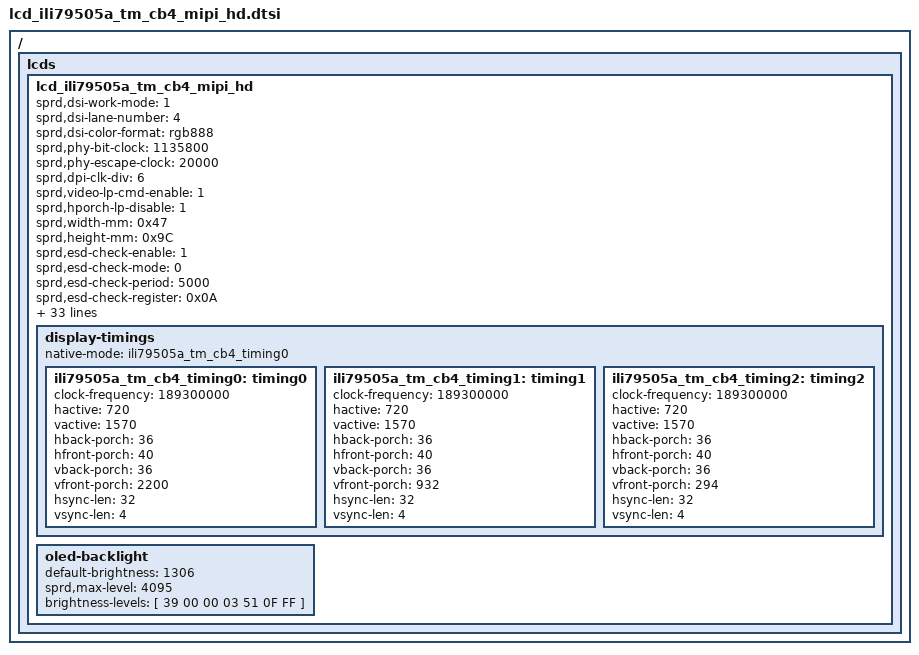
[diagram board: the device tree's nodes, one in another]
/*
 * R61350 Truly LCD config dtsi file for spreadtrum
 *
 * Copyright (C) 2018, Spreadtrum Communications Inc.
 *
 * SPDX-License-Identifier: (GPL-2.0+ OR MIT)
 */

/ {
    fragment {
        target-path = "/";
        __overlay__ {
            lcds {
                lcd_ili79505a_tm_cb4_mipi_hd: lcd_ili79505a_tm_cb4_mipi_hd {

                sprd,dsi-work-mode = <1>; /* video burst mode*/
                sprd,dsi-lane-number = <4>;
                sprd,dsi-color-format = "rgb888";

                sprd,phy-bit-clock = <1135800>; /* kbps */
                sprd,phy-escape-clock = <20000>;/* kHz */
                sprd,dpi-clk-div = <6>;
                sprd,video-lp-cmd-enable = <1>;
                sprd,hporch-lp-disable = <1>;

                sprd,width-mm = <0x47>;
                sprd,height-mm = <0x9C>;
                sprd,esd-check-enable = <1>;
                sprd,esd-check-mode = <0>;
                sprd,esd-check-period = <5000>;
                sprd,esd-check-register = <0x0A>;
                sprd,esd-check-value = <0x9C>;
                sprd,vrr-enabled;
                sprd,vrr-max-layers = <2>;

                sprd,low-brightness = <1>;

                sprd,power-i2c-bus = <4>;
                sprd,power-i2c-addr = <0x3e>;
                sprd,power-i2c-reg = [00 01 03];
                sprd,power-i2c-val = [14 14 33];

                sprd,reset-on-sequence = <1 5>, <0 5>, <1 5>;
                sprd,reset-off-sequence = <1 5>;

                sprd,tp-resume-by-ddic = <1>;
                sprd,tp-aod-support = <1>;

                sprd,mipi-lastframe-delay = <5>; //ms
                sprd,mipi-lastframe-delay-switch = <1>; //1 on; 0 off

                /*
                 * Use 4 bits number for descripting video lp mode, and it can be combined used.
                 * BIT(0): allow vactive enter lp;
                 * BIT(1): allow vfp enter lp;
                 * BIT(2): allow vbp enter lp;
                 * BIT(3): allow vsa enter lp;
                 * For example:
                 * If we need vfp & vbp enter lp, we can calculate this value as a result of BIT(1) | BIT(2)
                 * And we get the result of 3 and set this value to lcd dt property sprd,video-lp-en-mode.
                 * If we need all stage can enter lp, we can calculate this value as a result of BIT(0) | BIT(1) | BIT(2) | BIT(3).
                 * And we get the result of 15 and set this value to lcd dt property sprd,video-lp-en-mode.
                 */
                /*sprd,video-lp-en-mode = <2>;*/
                sprd,use-dcs-write;
                sprd,initial-command = [
                39 00 00 04 FF 5A A5 06
                23 00 00 02 07 A4
                39 00 00 04 FF 5A A5 03
                23 00 00 02 83 20
                23 00 00 02 84 01
                39 00 00 04 FF 5A A5 00
                23 00 00 02 53 2C
                23 00 00 03 51 0f ff
                23 00 00 03 68 04 00
                23 00 00 02 35 00
                23 3d 00 02 11 00
                23 60 00 02 29 00
                ];

                sprd,sleep-in-command = [
                05 32 00 01 28
                05 78 00 01 10
                ];

                sprd,sleep-in-command-gesture-off = [
                05 32 00 01 28
                05 78 00 01 10
                ];

                sprd,sleep-out-command = [
                05 80 00 01 11
                05 14 00 01 29
                ];

                sprd,doze-in-command = [
                23 00 00 02 53 24
                ];

                sprd,doze-out-command = [
                23 00 00 02 53 2C
                ];

                sprd,cabc-off-command = [
                39 00 00 04 FF 5A A5 00
                23 00 00 02 55 01
                ];
                sprd,cabc-ui-command = [
                39 00 00 04 FF 5A A5 00
                23 00 00 02 55 01
                ];
                sprd,cabc-still-command = [
                39 00 00 04 FF 5A A5 00
                23 00 00 02 55 02
                ];
                sprd,cabc-moving-command = [
                39 00 00 04 FF 5A A5 00
                23 00 00 02 55 03
                ];

                display-timings {
                    native-mode = <&ili79505a_tm_cb4_timing0>;

                    ili79505a_tm_cb4_timing0: timing0 {
                            clock-frequency = <189300000>;
							hactive = <720>;
							vactive = <1570>;
							hback-porch = <36>;
							hfront-porch = <40>;
							vback-porch = <36>;
							vfront-porch = <2200>;
							hsync-len = <32>;
							vsync-len = <4>;
                    };
                    ili79505a_tm_cb4_timing1: timing1 {
                       clock-frequency = <189300000>;
							hactive = <720>;
							vactive = <1570>;
							hback-porch = <36>;
							hfront-porch = <40>;
							vback-porch = <36>;
							vfront-porch = <932>;
							hsync-len = <32>;
							vsync-len = <4>;
                    };
                    ili79505a_tm_cb4_timing2: timing2 {
                        clock-frequency = <189300000>;
							hactive = <720>;
							vactive = <1570>;
							hback-porch = <36>;
							hfront-porch = <40>;
							vback-porch = <36>;
							vfront-porch = <294>;
							hsync-len = <32>;
							vsync-len = <4>;
                    };
                };

                oled-backlight {
                        default-brightness = <1306>;
                        sprd,max-level = <4095>;
                        brightness-levels = [
                        39 00 00 03 51 0F FF
                        ];
                    };
                };
            };
        };
    };
};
